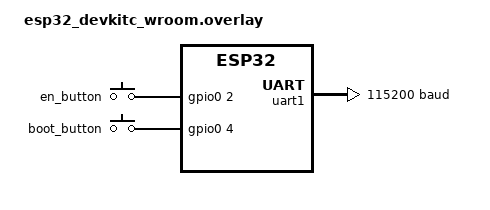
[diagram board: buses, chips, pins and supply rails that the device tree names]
/*
 * Copyright (c) 2022 Espressif Systems (Shanghai) Co., Ltd.
 *
 * SPDX-License-Identifier: Apache-2.0
 */

#include <zephyr/dt-bindings/pinctrl/esp-pinctrl-common.h>
#include <dt-bindings/pinctrl/esp32-pinctrl.h>
#include <zephyr/dt-bindings/pinctrl/esp32-gpio-sigmap.h>

/ {
	aliases {
		en = &en_button;
		boot = &boot_button;
		uart1 = &uart1;
	};

	gpio_keys {
		compatible = "gpio-keys";
		en_button: en_button {
			gpios = <&gpio0 2 (GPIO_PULL_UP | GPIO_ACTIVE_HIGH)>;
		};
		boot_button: boot_button {
			gpios = <&gpio0 4 (GPIO_PULL_UP | GPIO_ACTIVE_HIGH)>;
		};
	};
};

&uart1 {
	status = "okay";
	current-speed = <115200>;
	pinctrl-0 = <&uart1_default>;
	pinctrl-names = "default";
};
